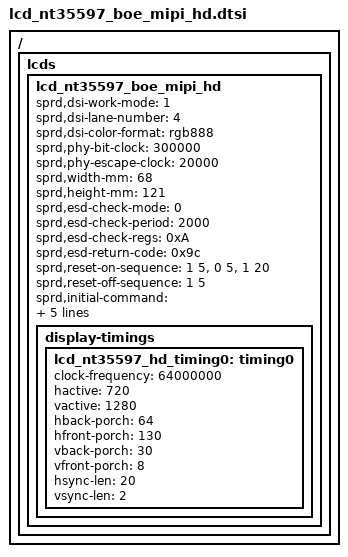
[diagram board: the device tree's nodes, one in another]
/*
 * NT35597 BOE HD Scaling-Up LCD config dtsi file for spreadtrum
 *
 * Copyright (C) 2018, Spreadtrum Communications Inc.
 *
 * SPDX-License-Identifier: (GPL-2.0+ OR MIT)
 */

/ { lcds {
	lcd_nt35597_boe_mipi_hd: lcd_nt35597_boe_mipi_hd {

		sprd,dsi-work-mode = <1>; /* video burst mode*/
		sprd,dsi-lane-number = <4>;
		sprd,dsi-color-format = "rgb888";

		sprd,phy-bit-clock = <300000>;	/* kbps */
		sprd,phy-escape-clock = <20000>;/* kHz */

		sprd,width-mm = <68>;
		sprd,height-mm = <121>;

		sprd,esd-check-mode = <0>;
		sprd,esd-check-period = <2000>;
		sprd,esd-check-regs = <0xA>;
		sprd,esd-return-code = <0x9c>;

		sprd,reset-on-sequence = <1 5>, <0 5>, <1 20>;
		sprd,reset-off-sequence = <1 5>;

		sprd,initial-command = [
			23 00 00 02 FF 20
			23 00 00 02 FB 01
			23 00 00 02 00 01
			23 00 00 02 01 55
			23 00 00 02 02 45
			23 00 00 02 05 40
			23 00 00 02 06 9a
			23 00 00 02 07 9E
			23 00 00 02 11 91
			23 00 00 02 13 00
			23 00 00 02 0B 9B
			23 00 00 02 0C 9B
			23 00 00 02 0E a4
			23 00 00 02 0F a0
			23 00 00 02 30 00
			23 00 00 02 56 00
			23 00 00 02 58 00
			23 00 00 02 59 00
			23 00 00 02 5A 00
			23 00 00 02 5B 00
			23 00 00 02 5C 00
			23 00 00 02 5D 00
			23 00 00 02 5E 00
			23 00 00 02 5F 00
			23 00 00 02 60 80
			23 00 00 02 61 04
			23 00 00 02 62 00
			23 00 00 02 63 03
			23 00 00 02 68 03
			23 00 00 02 6D 66
			23 00 00 02 72 31
			23 00 00 02 FF 20
			23 00 00 02 FB 01
			23 00 00 02 75 00
			23 00 00 02 76 00
			23 00 00 02 77 00
			23 00 00 02 78 12
			23 00 00 02 79 00
			23 00 00 02 7A 2E
			23 00 00 02 7B 00
			23 00 00 02 7C 45
			23 00 00 02 7D 00
			23 00 00 02 7E 5A
			23 00 00 02 7F 00
			23 00 00 02 80 6D
			23 00 00 02 81 00
			23 00 00 02 82 7F
			23 00 00 02 83 00
			23 00 00 02 84 8F
			23 00 00 02 85 00
			23 00 00 02 86 9E
			23 00 00 02 87 00
			23 00 00 02 88 D2
			23 00 00 02 89 00
			23 00 00 02 8A FA
			23 00 00 02 8B 01
			23 00 00 02 8C 38
			23 00 00 02 8D 01
			23 00 00 02 8E 66
			23 00 00 02 8F 01
			23 00 00 02 90 AC
			23 00 00 02 91 01
			23 00 00 02 92 E4
			23 00 00 02 93 01
			23 00 00 02 94 E5
			23 00 00 02 95 02
			23 00 00 02 96 18
			23 00 00 02 97 02
			23 00 00 02 98 58
			23 00 00 02 99 02
			23 00 00 02 9A 82
			23 00 00 02 9B 02
			23 00 00 02 9C BD
			23 00 00 02 9D 02
			23 00 00 02 9E E6
			23 00 00 02 9F 03
			23 00 00 02 A0 1A
			23 00 00 02 A2 03
			23 00 00 02 A3 2B
			23 00 00 02 A4 03
			23 00 00 02 A5 3D
			23 00 00 02 A6 03
			23 00 00 02 A7 51
			23 00 00 02 A9 03
			23 00 00 02 AA 69
			23 00 00 02 AB 03
			23 00 00 02 AC 85
			23 00 00 02 AD 03
			23 00 00 02 AE A8
			23 00 00 02 AF 03
			23 00 00 02 B0 CC
			23 00 00 02 B1 03
			23 00 00 02 B2 D2
			23 00 00 02 B3 00
			23 00 00 02 B4 00
			23 00 00 02 B5 00
			23 00 00 02 B6 12
			23 00 00 02 B7 00
			23 00 00 02 B8 2E
			23 00 00 02 B9 00
			23 00 00 02 BA 45
			23 00 00 02 BB 00
			23 00 00 02 BC 5A
			23 00 00 02 BD 00
			23 00 00 02 BE 6D
			23 00 00 02 BF 00
			23 00 00 02 C0 7F
			23 00 00 02 C1 00
			23 00 00 02 C2 8F
			23 00 00 02 C3 00
			23 00 00 02 C4 9E
			23 00 00 02 C5 00
			23 00 00 02 C6 D2
			23 00 00 02 C7 00
			23 00 00 02 C8 FA
			23 00 00 02 C9 01
			23 00 00 02 CA 38
			23 00 00 02 CB 01
			23 00 00 02 CC 66
			23 00 00 02 CD 01
			23 00 00 02 CE AC
			23 00 00 02 CF 01
			23 00 00 02 D0 E4
			23 00 00 02 D1 01
			23 00 00 02 D2 E5
			23 00 00 02 D3 02
			23 00 00 02 D4 18
			23 00 00 02 D5 02
			23 00 00 02 D6 58
			23 00 00 02 D7 02
			23 00 00 02 D8 82
			23 00 00 02 D9 02
			23 00 00 02 DA BD
			23 00 00 02 DB 02
			23 00 00 02 DC E6
			23 00 00 02 DD 03
			23 00 00 02 DE 1A
			23 00 00 02 DF 03
			23 00 00 02 E0 2B
			23 00 00 02 E1 03
			23 00 00 02 E2 3D
			23 00 00 02 E3 03
			23 00 00 02 E4 51
			23 00 00 02 E5 03
			23 00 00 02 E6 69
			23 00 00 02 E7 03
			23 00 00 02 E8 85
			23 00 00 02 E9 03
			23 00 00 02 EA A8
			23 00 00 02 EB 03
			23 00 00 02 EC CC
			23 00 00 02 ED 03
			23 00 00 02 EE D2
			23 00 00 02 EF 00
			23 00 00 02 F0 00
			23 00 00 02 F1 00
			23 00 00 02 F2 12
			23 00 00 02 F3 00
			23 00 00 02 F4 2E
			23 00 00 02 F5 00
			23 00 00 02 F6 45
			23 00 00 02 F7 00
			23 00 00 02 F8 5A
			23 00 00 02 F9 00
			23 00 00 02 FA 6D
			23 00 00 02 FF 21
			23 00 00 02 FB 01
			23 00 00 02 00 00
			23 00 00 02 01 7F
			23 00 00 02 02 00
			23 00 00 02 03 8F
			23 00 00 02 04 00
			23 00 00 02 05 9E
			23 00 00 02 06 00
			23 00 00 02 07 D2
			23 00 00 02 08 00
			23 00 00 02 09 FA
			23 00 00 02 0A 01
			23 00 00 02 0B 38
			23 00 00 02 0C 01
			23 00 00 02 0D 66
			23 00 00 02 0E 01
			23 00 00 02 0F AC
			23 00 00 02 10 01
			23 00 00 02 11 E4
			23 00 00 02 12 01
			23 00 00 02 13 E5
			23 00 00 02 14 02
			23 00 00 02 15 18
			23 00 00 02 16 02
			23 00 00 02 17 58
			23 00 00 02 18 02
			23 00 00 02 19 82
			23 00 00 02 1A 02
			23 00 00 02 1B BD
			23 00 00 02 1C 02
			23 00 00 02 1D E6
			23 00 00 02 1E 03
			23 00 00 02 1F 1A
			23 00 00 02 20 03
			23 00 00 02 21 2B
			23 00 00 02 22 03
			23 00 00 02 23 3D
			23 00 00 02 24 03
			23 00 00 02 25 51
			23 00 00 02 26 03
			23 00 00 02 27 69
			23 00 00 02 28 03
			23 00 00 02 29 85
			23 00 00 02 2A 03
			23 00 00 02 2B A8
			23 00 00 02 2D 03
			23 00 00 02 2F CC
			23 00 00 02 30 03
			23 00 00 02 31 D2
			23 00 00 02 32 00
			23 00 00 02 33 00
			23 00 00 02 34 00
			23 00 00 02 35 12
			23 00 00 02 36 00
			23 00 00 02 37 2E
			23 00 00 02 38 00
			23 00 00 02 39 45
			23 00 00 02 3A 00
			23 00 00 02 3B 5A
			23 00 00 02 3D 00
			23 00 00 02 3F 6D
			23 00 00 02 40 00
			23 00 00 02 41 7F
			23 00 00 02 42 00
			23 00 00 02 43 8F
			23 00 00 02 44 00
			23 00 00 02 45 9E
			23 00 00 02 46 00
			23 00 00 02 47 D2
			23 00 00 02 48 00
			23 00 00 02 49 FA
			23 00 00 02 4A 01
			23 00 00 02 4B 38
			23 00 00 02 4C 01
			23 00 00 02 4D 66
			23 00 00 02 4E 01
			23 00 00 02 4F AC
			23 00 00 02 50 01
			23 00 00 02 51 E4
			23 00 00 02 52 01
			23 00 00 02 53 E5
			23 00 00 02 54 02
			23 00 00 02 55 18
			23 00 00 02 56 02
			23 00 00 02 58 58
			23 00 00 02 59 02
			23 00 00 02 5A 82
			23 00 00 02 5B 02
			23 00 00 02 5C BD
			23 00 00 02 5D 02
			23 00 00 02 5E E6
			23 00 00 02 5F 03
			23 00 00 02 60 1A
			23 00 00 02 61 03
			23 00 00 02 62 2B
			23 00 00 02 63 03
			23 00 00 02 64 3D
			23 00 00 02 65 03
			23 00 00 02 66 51
			23 00 00 02 67 03
			23 00 00 02 68 69
			23 00 00 02 69 03
			23 00 00 02 6A 85
			23 00 00 02 6B 03
			23 00 00 02 6C A8
			23 00 00 02 6D 03
			23 00 00 02 6E CC
			23 00 00 02 6F 03
			23 00 00 02 70 D2
			23 00 00 02 71 00
			23 00 00 02 72 00
			23 00 00 02 73 00
			23 00 00 02 74 12
			23 00 00 02 75 00
			23 00 00 02 76 2E
			23 00 00 02 77 00
			23 00 00 02 78 45
			23 00 00 02 79 00
			23 00 00 02 7A 5A
			23 00 00 02 7B 00
			23 00 00 02 7C 6D
			23 00 00 02 7D 00
			23 00 00 02 7E 7F
			23 00 00 02 7F 00
			23 00 00 02 80 8F
			23 00 00 02 81 00
			23 00 00 02 82 9E
			23 00 00 02 83 00
			23 00 00 02 84 D2
			23 00 00 02 85 00
			23 00 00 02 86 FA
			23 00 00 02 87 01
			23 00 00 02 88 38
			23 00 00 02 89 01
			23 00 00 02 8A 66
			23 00 00 02 8B 01
			23 00 00 02 8C AC
			23 00 00 02 8D 01
			23 00 00 02 8E E4
			23 00 00 02 8F 01
			23 00 00 02 90 E5
			23 00 00 02 91 02
			23 00 00 02 92 18
			23 00 00 02 93 02
			23 00 00 02 94 58
			23 00 00 02 95 02
			23 00 00 02 96 82
			23 00 00 02 97 02
			23 00 00 02 98 BD
			23 00 00 02 99 02
			23 00 00 02 9A E6
			23 00 00 02 9B 03
			23 00 00 02 9C 1A
			23 00 00 02 9D 03
			23 00 00 02 9E 2B
			23 00 00 02 9F 03
			23 00 00 02 A0 3D
			23 00 00 02 A2 03
			23 00 00 02 A3 51
			23 00 00 02 A4 03
			23 00 00 02 A5 69
			23 00 00 02 A6 03
			23 00 00 02 A7 85
			23 00 00 02 A9 03
			23 00 00 02 AA A8
			23 00 00 02 AB 03
			23 00 00 02 AC CC
			23 00 00 02 AD 03
			23 00 00 02 AE D2
			23 00 00 02 AF 00
			23 00 00 02 B0 00
			23 00 00 02 B1 00
			23 00 00 02 B2 12
			23 00 00 02 B3 00
			23 00 00 02 B4 2E
			23 00 00 02 B5 00
			23 00 00 02 B6 45
			23 00 00 02 B7 00
			23 00 00 02 B8 5A
			23 00 00 02 B9 00
			23 00 00 02 BA 6D
			23 00 00 02 BB 00
			23 00 00 02 BC 7F
			23 00 00 02 BD 00
			23 00 00 02 BE 8F
			23 00 00 02 BF 00
			23 00 00 02 C0 9E
			23 00 00 02 C1 00
			23 00 00 02 C2 D2
			23 00 00 02 C3 00
			23 00 00 02 C4 FA
			23 00 00 02 C5 01
			23 00 00 02 C6 38
			23 00 00 02 C7 01
			23 00 00 02 C8 66
			23 00 00 02 C9 01
			23 00 00 02 CA AC
			23 00 00 02 CB 01
			23 00 00 02 CC E4
			23 00 00 02 CD 01
			23 00 00 02 CE E5
			23 00 00 02 CF 02
			23 00 00 02 D0 18
			23 00 00 02 D1 02
			23 00 00 02 D2 58
			23 00 00 02 D3 02
			23 00 00 02 D4 82
			23 00 00 02 D5 02
			23 00 00 02 D6 BD
			23 00 00 02 D7 02
			23 00 00 02 D8 E6
			23 00 00 02 D9 03
			23 00 00 02 DA 1A
			23 00 00 02 DB 03
			23 00 00 02 DC 2B
			23 00 00 02 DD 03
			23 00 00 02 DE 3D
			23 00 00 02 DF 03
			23 00 00 02 E0 51
			23 00 00 02 E1 03
			23 00 00 02 E2 69
			23 00 00 02 E3 03
			23 00 00 02 E4 85
			23 00 00 02 E5 03
			23 00 00 02 E6 A8
			23 00 00 02 E7 03
			23 00 00 02 E8 CC
			23 00 00 02 E9 03
			23 00 00 02 EA D2
			23 00 00 02 FF E0
			23 00 00 02 FB 01
			23 00 00 02 3F 08
			23 00 00 02 6B 3D
			23 00 00 02 6C 3D
			23 00 00 02 6D 3D
			23 00 00 02 6E 3D
			23 00 00 02 6F 3D
			23 00 00 02 35 02
			23 00 00 02 36 72
			23 00 00 02 37 10
			23 00 00 02 FF 24
			23 00 00 02 FB 01
			23 00 00 02 00 0C
			23 00 00 02 01 0B
			23 00 00 02 02 0F
			23 00 00 02 03 08
			23 00 00 02 04 07
			23 00 00 02 05 01
			23 00 00 02 06 00
			23 00 00 02 07 00
			23 00 00 02 08 00
			23 00 00 02 09 00
			23 00 00 02 0A 00
			23 00 00 02 0B 17
			23 00 00 02 0C 00
			23 00 00 02 0D 15
			23 00 00 02 0E 00
			23 00 00 02 0F 13
			23 00 00 02 10 0C
			23 00 00 02 11 0B
			23 00 00 02 12 0F
			23 00 00 02 13 08
			23 00 00 02 14 07
			23 00 00 02 15 01
			23 00 00 02 16 00
			23 00 00 02 17 00
			23 00 00 02 18 00
			23 00 00 02 19 00
			23 00 00 02 1A 00
			23 00 00 02 1B 17
			23 00 00 02 1C 00
			23 00 00 02 1D 15
			23 00 00 02 1E 00
			23 00 00 02 1F 13
			23 00 00 02 20 09
			23 00 00 02 21 03
			23 00 00 02 22 03
			23 00 00 02 23 01
			23 00 00 02 24 72
			23 00 00 02 25 3D
			23 00 00 02 26 01
			23 00 00 02 27 72
			23 00 00 02 29 38
			23 00 00 02 2A 2B
			23 00 00 02 3F 04
			23 00 00 02 40 12
			23 00 00 02 41 e9
			23 00 00 02 42 01
			23 00 00 02 43 02
			23 00 00 02 44 70
			23 00 00 02 45 00
			23 00 00 02 46 2d
			23 00 00 02 47 08
			23 00 00 02 48 02
			23 00 00 02 49 70
			23 00 00 02 5B 00
			23 00 00 02 5F 75
			23 00 00 02 63 04
			23 00 00 02 67 70
			23 00 00 02 b5 15
			23 00 00 02 72 02
			23 00 00 02 7A 00
			23 00 00 02 7B A2
			23 00 00 02 7C D8
			23 00 00 02 7D 50
			23 00 00 02 74 0D
			23 00 00 02 75 19
			23 00 00 02 7F 19
			23 00 00 02 86 5B
			23 00 00 02 87 39
			23 00 00 02 88 1b
			23 00 00 02 89 39
			23 00 00 02 8C 11
			23 00 00 02 B3 00
			23 00 00 02 B4 01
			23 00 00 02 B5 00
			23 00 00 02 78 00
			23 00 00 02 79 00
			23 00 00 02 80 00
			23 00 00 02 83 00
			23 00 00 02 93 10
			23 00 00 02 94 10
			23 00 00 02 8A 33
			23 00 00 02 8B F4
			23 00 00 02 9B 0F
			23 00 00 02 9d 30
			23 00 00 02 EC 00
			23 00 00 02 FF 22
			23 00 00 02 Fb 01
			23 00 00 02 A2 20
			23 00 00 02 FF 28
			23 00 00 02 Fb 01
			23 00 00 02 7A 02
			23 00 00 02 FF 10
			23 00 00 02 Fb 01
		//	39 00 00 06 3B 03 08 08 40 40	//3B 03 VBP+VSYNC VFP HBP HFP
			39 00 00 06 3B 03 20 08 40 40	//3B 03 VBP+VSYNC VFP HBP HFP
			23 00 00 02 35 00
			39 00 00 11 C1 09 20 0A 00 01 DB 02 68 E4 BD 00 0A 00 0A 00 08
			39 00 00 03 C2 12 18
			23 00 00 02 C0 00
			23 00 00 02 BB 10	//cmd mode with GRAM
		//	23 00 00 02 BB 13	//video mode with GRAM
			13 78 00 01 11
			13 64 00 01 29
			23 00 00 02 58 01	//scaling-up mode
			];

		sprd,sleep-in-command = [
			13 0A 00 01 28
			13 78 00 01 10
			23 00 00 02 4F 01
			];

		sprd,sleep-out-command = [
			13 78 00 01 11
			13 64 00 01 29
			];

		display-timings {
			lcd_nt35597_hd_timing0: timing0 {
				clock-frequency = <64000000>;
				hactive = <720>;
				vactive = <1280>;
				hback-porch = <64>;
				hfront-porch = <130>;
				vback-porch = <30>;
				vfront-porch = <8>;
				hsync-len = <20>;
				vsync-len = <2>;
			};
		};
	};
};};
